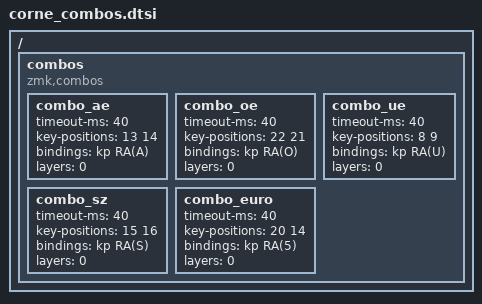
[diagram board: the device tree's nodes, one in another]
/ {
    combos {
        compatible = "zmk,combos";
        
        combo_ae {
            timeout-ms = <40>;
            key-positions = <13 14>;  // a+r
            bindings = <&kp RA(A)>;  // ä/Ä
            layers = <0>;
        };
        
        combo_oe {
            timeout-ms = <40>;
            key-positions = <22 21>;  // o+i
            bindings = <&kp RA(O)>;  // ö/Ö
            layers = <0>;
        };
        
        combo_ue {
            timeout-ms = <40>;
            key-positions = <8 9>;  // u+y
            bindings = <&kp RA(U)>;  // ü/Ü
            layers = <0>;
        };
        
        combo_sz {
            timeout-ms = <40>;
            key-positions = <15 16>;  // s+t
            bindings = <&kp RA(S)>;  // ß (no uppercase, use 0)
            layers = <0>;
        };
        
        combo_euro {
            timeout-ms = <40>;
            key-positions = <20 14>;  // e+r
            bindings = <&kp RA(5)>;  // €
            layers = <0>;
        };
    };
};
